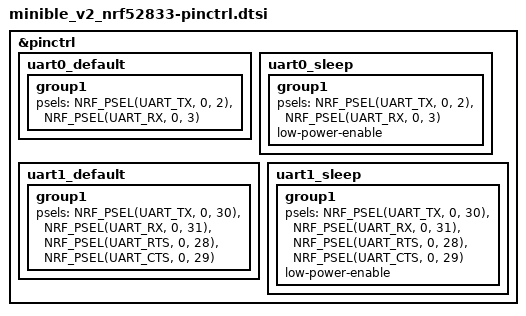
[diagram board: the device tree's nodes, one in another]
/*
 * SPDX-License-Identifier: Apache-2.0
 */

&pinctrl {
	uart0_default: uart0_default {
		group1 {
			psels = <NRF_PSEL(UART_TX, 0, 2)>,
				<NRF_PSEL(UART_RX, 0, 3)>;
		};
	};

	uart0_sleep: uart0_sleep {
		group1 {
			psels = <NRF_PSEL(UART_TX, 0, 2)>,
				<NRF_PSEL(UART_RX, 0, 3)>;
			low-power-enable;
		};
	};
	
	uart1_default: uart1_default {
		group1 {
			psels = <NRF_PSEL(UART_TX, 0, 30)>,
				<NRF_PSEL(UART_RX, 0, 31)>,
				<NRF_PSEL(UART_RTS, 0, 28)>,
				<NRF_PSEL(UART_CTS, 0, 29)>;
		};
	};

	uart1_sleep: uart1_sleep {
		group1 {
			psels = <NRF_PSEL(UART_TX, 0, 30)>,
				<NRF_PSEL(UART_RX, 0, 31)>,
				<NRF_PSEL(UART_RTS, 0, 28)>,
				<NRF_PSEL(UART_CTS, 0, 29)>;
			low-power-enable;
		};
	};
};
